# DCAN2 register map
Vendor: Texas Instruments
Peripheral module from a debugger description file (folder DM50x).
Registers are 32-bit, read-only, reset 0x0 unless marked. A register's access mark holds for its fields unless they carry their own. Offsets are as the file gives them; lines under a group give offsets from that group; [hi:lo] are bit positions; {n}, {i} and the like mark numbered series; 'fields as' and 'values as' point back to an identical list; <NAME> marks a mode.

## DCAN2 (part 1 of 2)
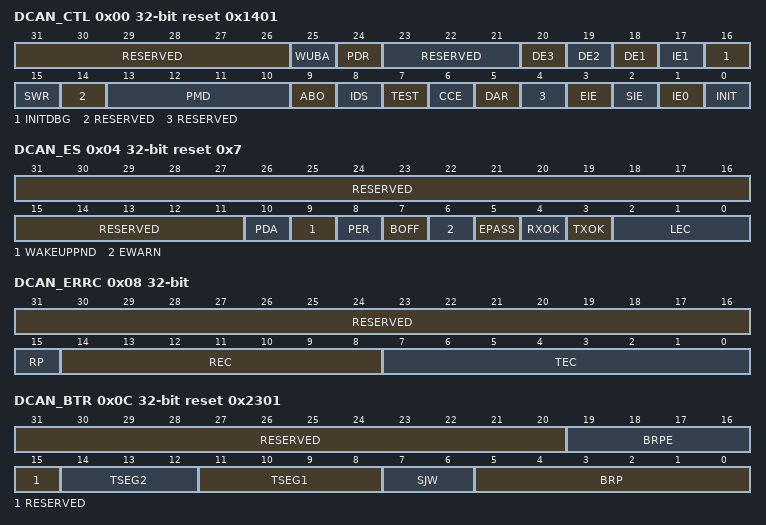
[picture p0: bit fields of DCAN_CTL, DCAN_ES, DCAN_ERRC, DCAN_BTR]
0x00 DCAN_CTL access per field reset 0x1401 — DCAN control register NOTE: The Bus-Off recovery sequence (refer to CAN specification) cannot be shortened by setting or resetting INIT bit. If the module goes Bus-Off, it will automatically set the INIT bit and stop all bus activities. When the INIT bit is cleared by the application again, the module will then wait for 129 occurrences of Bus Idle (129 × 11 consecutive recessive bits) before resuming normal operation. At the end of the bus-off recovery sequence, the error counters will be reset. After the INIT bit is reset, each time when a sequence of 11 recessive bits is monitored, a Bit0 error code is written to , enabling the software to check whether the CAN bus is stuck at dominant or continuously disturbed, and to monitor the proceeding of the bus-off recovery sequence.
  [31:26] RESERVED ro — These bits are always read as 0. Writes have no effect.
  [25] WUBA rw — Automatic wake up on bus activity when in local power-down mode. Note: The CAN message, which initiates the bus activity, cannot be received. This means that the first message received in power down and automatic wake-up mode, will be lost.
    0=CAN_0 (No detection of a dominant CAN bus level while in local power-down mode.); 1=CAN_CAN_1 (Detection of a dominant CAN bus level while in local power-down mode is enabled. On occurrence of a dominant CAN bus level, the wake up sequence is started (Additional information can be found inLocal Power-Down Mode).)
  [24] PDR rw — Request for local low power-down mode
    0=DCAN_INIT_0 (No application request for local low power-down mode. If the application has cleared this bit while DCAN in local power-down mode, also the INIT bit has to be cleared.); 1=DCAN_PDA_DCAN_1 (Local power-down mode has been requested by application. The DCAN will acknowledge the local power-down mode by setting bit PDA in the register. The local clocks will be turned off by DCAN internal logic (Additional information can be found in Local Power-Down Mode).)
  [23:21] RESERVED ro — These bits are always read as 0. Writes have no effect.
  [20] DE3 rw — Enable DMA request line for IF3. Note: A pending DMA request for IF3 remains active until first access to one of the IF3 registers.
    0=Disabled; 1=Enabled
  [19] DE2 rw — Enable DMA request line for IF2. Note: A pending DMA request for IF2 remains active until first access to one of the IF2 registers.
    0=Disabled; 1=Enabled
  [18] DE1 rw — Enable DMA request line for IF1. Note: A pending DMA request for IF1 remains active until first access to one of the IF1 registers.
    0=Disabled; 1=Enabled
  [17] IE1 rw — Interrupt line 1 enable
    0=INT1_0 (Disabled - Module interrupt INT1 is always low.); 1=INT1_1 (Enabled - interrupts will assert line INT1 to one; line remains active until pending interrupts are processed.)
  [16] INITDBG rw — Internal init state while debug access
    0=Not in debug mode, or debug mode requested but not entered; 1=DCAN_1 (Debug mode requested and internally entered; the DCAN is ready for debug accesses.)
  [15] SWR rw — Software reset enable. Note: To execute software reset, the following procedure is necessary:
    0=Normal_Operation; 1=OCP_1 (Module is forced to reset state. This bit will automatically get cleared after execution of software reset after one OCP clock cycle.)
  [14] RESERVED ro — This bit is always read as 0. Writes have no effect.
  [13:10] PMD rw — ECCon/offOthers: function enabled .
    5=function_disabled
  [9] ABO rw — Auto-Bus-On enable
    0=The_Auto-Bus-On_feature_is_disabled; 1=The_Auto-Bus-On_feature_is_enabled
  [8] IDS rw — Interruption debug support enable
    0=DCAN_0 (When Debug/Suspend mode is requested, DCAN will wait for a started transmission or reception to be completed before entering Debug/Suspend mode); 1=DCAN_1 (When Debug/Suspend mode is requested, DCAN will interrupt any transmission or reception, and enter Debug/Suspend mode immediately.)
  [7] TEST rw — Test mode enable
    0=Normal_Operation; 1=Test_Mode
  [6] CCE rw — Configuration change enable
    0=The software has no write access to the configuration registers; 1=INIT_1 (The software has write access to the configuration registers (when INIT bit is set).)
  [5] DAR rw — Disable automatic retransmission
    0=Automatic retransmission of not successful messages enabled; 1=Automatic_retransmission_disabled
  [4] RESERVED ro — This bit is always read as 0. Writes have no effect.
  [3] EIE rw — Error interrupt enable
    0=PER,_BOFF_EWARN_0 (Disabled - PER, BOFF and EWARN bits can not generate an interrupt.); 1=PER,_BOFF_EWARN_INT0_1 (Enabled - PER, BOFF and EWARN bits can generate an interrupt at INT0 line and affect the interrupt register.)
  [2] SIE rw — Status change interrupt enable
    0=WAKEUPPND,_RXOK,_TXOK_LEC_0 (Disabled - WAKEUPPND, RXOK, TXOK and LEC bits can not generate an interrupt.); 1=WAKEUPPND,_RXOK,_TXOK_LEC_INT0_1 (Enabled - WAKEUPPND, RXOK, TXOK and LEC can generate an interrupt at INT0 line and affect the interrupt register.)
  [1] IE0 rw — Interrupt line 0 enable
    0=INT0_0 (Disabled - Module interrupt INT0 is always low.); 1=INT0_1 (Enabled - interrupts will assert line INT0 to one; line remains active until pending interrupts are processed.)
  [0] INIT rw — Initialization
    0=Normal_operation; 1=Initialization_mode_is_entered
0x04 DCAN_ES access per field reset 0x7 — Error and Status Register Interrupts are generated by bits PER, BOFF and EWARN (if EIE bit in is 1) and by bits WAKEUPPND, RXOK, TXOK, and LEC (if SIE bit in is 1). A change of bit EPASS will not generate an interrupt. Reading the clears the WAKEUPPND, PER, RXOK and TXOK bits and set the LEC to value '7.' Additionally, the status interrupt value (0x8000) in the will be replaced by the next lower priority interrupt value. For debug support, the auto clear functionality of (clear of status flags by read) is disabled when in debug/suspend mode.
  [31:11] RESERVED ro — These bits are always read as 0. Writes have no effect.
  [10] PDA ro — Local power-down mode acknowledge
    0=DCAN_is_not_in_local_power-down_mode; 1=DCAN_DCAN_1 (Application request for setting DCAN to local power-down mode was successful. DCAN is in local power-down mode.)
  [9] WAKEUPPND ro — Wake up pending. This bit can be used by the software to identify the DCAN as the source to wake up the system. This bit will be reset ifDCAN_ES is read. .
    0=No_Wake_Up_is_requested_by_DCAN; 1=DCAN_CAN_1 (DCAN has initiated a wake up of the system due to dominant CAN bus while module power down.)
  [8] PER rw — Parity error detected. This bit will be reset ifDCAN_ES register is read.
    0=PER_0_r (No parity error has been detected since last read access.); 1=RAM._1 (The parity check mechanism has detected a parity error in the Message RAM.); 0=No_effect; 1=(EOI)_DCAN_PARITY_1 (End of interrupt (EOI) for parity error on DCAN_PARITY interrupt line)
  [7] BOFF ro — Bus-Off state
    0=The_CAN_module_is_not_bus-off_state; 1=The_CAN_module_is_in_bus-off_state
  [6] EWARN ro — Warning state
    0=Both error counters are below the error warning limit of 96; 1=At least one of the error counters has reached the error warning limit of 96
  [5] EPASS ro — Error passive state
    0=CAN_DCAN_0 (On CAN Bus error, the DCAN could send active error frames.); 1=CAN_CAN_1 (The CAN core is in the error passive state as defined in the CAN Specification.)
  [4] RXOK ro — Received a message successfully. This bit will be reset ifDCAN_ES register is read. .
    0=DCAN_0 (No message has been successfully received since the last time when this bit was read by the software. This bit is never reset by DCAN internal events.); 1=A_1 (A message has been successfully received since the last time when this bit was reset by a read access of the software (independent of the result of acceptance filtering).)
  [3] TXOK ro — Transmitted a message successfully. This bit will be reset ifDCAN_ES register is read. .
    0=DCAN_0 (No message has been successfully transmitted since the last time when this bit was read by the software. This bit is never reset by DCAN internal events.); 1=A_1 (A message has been successfully transmitted (error free and acknowledged by at least one other node) since the last time when this bit was reset by a read access of the software.)
  [2:0] LEC ro — Last error code. The LEC field indicates the type of the last error on the CAN bus. This field will be cleared to '0' when a message has been transferred (reception or transmission) without error.
    0=No_error; 1=Stuff error: More than five equal bits in a row have been detected in a part of a received message where this is not allowed; 2=A_2 (Form error: A fixed format part of a received frame has the wrong format.); 3=CAN_3 (Ack error: The message this CAN core transmitted was not acknowledged by another node.); 4=Bit1 error: During the transmission of a message (with the exception of the arbitration field), the device wanted to send a recessive level (bit of logical value '1'), but the monitored bus value was dominant; 5=Bit0 error: During the transmission of a message (or acknowledge bit, or active error flag, or overload flag), the device wanted to send a dominant level (logical value '0'), but the monitored bus level was recessive. During Bus-Off recovery, this status is set each time a sequence of 11 recessive bits has been monitored. This enables the software to monitor the proceeding of the Bus-Off recovery sequence (indicating the bus is not stuck at dominant or continuously disturbed).; 6=CRC_CRC_(CRC_CRC_6 (CRC error: In a received message, the CRC check sum was incorrect. (CRC received for an incoming message does not match the calculated CRC for the received data).); 7=CAN_LEC_7 (No CAN bus event was detected since the last time the software read. Any read access to re-initializes the LEC to value '7.')
0x08 DCAN_ERRC — Error Counter Register
  [31:16] RESERVED — These bits are always read as 0. Writes have no effect.
  [15] RP — Receive error passive
    0=The receive error counter is below the error passive level; 1=CAN_1 (The receive error counter has reached the error passive level as defined in the CAN specification.)
  [14:8] REC — Receive error counter. Actual state of the receive error counter
  [7:0] TEC — Transmit error counter. Actual state of the transmit error counter
0x0C DCAN_BTR access per field reset 0x2301 — Bit timing register This register is only writable if CCE and INIT bits in the are set. The CAN bit time may be programmed in the range of 8 to 25 time quanta The CAN time quantum may be programmed in the range of 1 to 1024 CAN_CLK periods.
  [31:20] RESERVED ro — These bits are always read as 0. Writes have no effect.
  [19:16] BRPE rw — Baud rate prescaler extension.Valid programmed values are 0 to 15. . By programming BRPE the baud rate prescaler can be extended to values up to 1024. .
  [15] RESERVED ro — These bits are always read as 0. Writes have no effect.
  [14:12] TSEG2 rw — Time segment after the sample pointValid programmed values are 0 to 7. . The actual TSeg2 value which is interpreted for the bit timing will be the programmed TSeg2 value + 1. .
  [11:8] TSEG1 rw — Time segment before the sample pointValid programmed values are 1 to15. . The actual TSeg1 value interpreted for the bit timing will be the programmed TSeg1 value + 1. .
  [7:6] SJW rw — Synchronization Jump WidthValid programmed values are 0 to 3. . The actual SJW value interpreted for the synchronization will be the programmed SJW value + 1. .
  [5:0] BRP rw — Baud rate prescalerValue by which the CAN_CLK frequency is divided for generating the bit time quanta. The bit time is built up from a multiple of this quanta. . Valid programmed values are 0 to 63. . The actual BRP value interpreted for the bit timing will be the programmed BRP value + 1. .
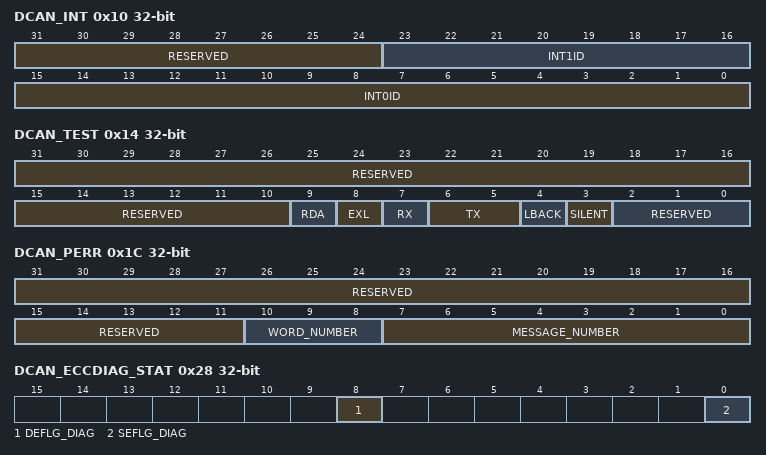
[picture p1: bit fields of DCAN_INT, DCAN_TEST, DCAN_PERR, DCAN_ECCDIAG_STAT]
0x10 DCAN_INT — Interrupt register
  [31:24] RESERVED — These bits are always read as 0. Writes have no effect.
  [23:16] INT1ID — Interrupt 1 Identifier (indicates the message object with the highest pending interrupt)0x01-0x80: Number of message object which caused the interrupt. . 0x81-0xFF: Unused . If several interrupts are pending, will point to the pending interrupt with the highest priority. The INT1 interrupt line remains active until INT1ID reaches value 0 (the cause of the interrupt is reset) or until IE1 is cleared. . A message interrupt is cleared by clearing the message object's IntPnd bit. . Among the message interrupts, the message object's interrupt priority decreases with increasing message number. .
    0=No_interrupt_is_pending
  [15:0] INT0ID — Interrupt Identifier (the number here indicates the source of the interrupt)0x0001-0x0080: Number of message object which caused the interrupt. . 0x0081-0x7FFF: Unused . 0x8001-0xFFFF: Unused . If several interrupts are pending,DCAN_INTwill point to the pending interrupt with the highest priority. The INT0 interrupt line remains active until INT0ID reaches value 0 (the cause of the interrupt is reset) or until IE0 is cleared. . The Status interrupt has the highest priority. Among the message interrupts, the message object's interrupt priority decreases with increasing message number. .
    0=No_interrupt_is_pending; 0x8000=value_is_not_0x07
0x14 DCAN_TEST access per field (reset mask 0xFFFFFF7F) — Test Register For all test modes, the TEST bit in control register needs to be set to 1. If TEST bit is set, the RDA, EXL, TX1, TX0, LBACK and SILENT bits are writable. Bit RX monitors the state of pin CAN_RX and therefore is only readable. All test register functions are disabled when TEST bit is cleared.
  [31:10] RESERVED ro — These bits are always read as 0. Writes have no effect.
  [9] RDA rw — RAM direct access enable
    0=Normal_operation; 1=RAM_1 (Direct access to the RAM is enabled while in test mode)
  [8] EXL rw — External loopback mode. When the internal loop-back mode is active (bit LBACK is set), bit EXL will be ignored.
    0=Disabled; 1=Enabled
  [7] RX ro — Receive pin. Monitors the actual value of the CAN_RX pin
    0=The_CAN_bus_is_dominant; 1=The_CAN_bus_is_recessive
  [6:5] TX rw — Control of CAN_TX pin. Setting Tx[1:0] other than '00' will disturb message transfer.
    0=CAN_TX_CAN_0 (Normal operation, CAN_TX is controlled by the CAN core.); 1=CAN_TX_1 (Sample point can be monitored at CAN_TX pin.); 2=CAN_TX_pin_drives_a_dominant_value; 3=CAN_TX_pin_drives_a_recessive_value
  [4] LBACK rw — Loopback mode. When the internal loop-back mode is active (bit LBACK is set), bit EXL will be ignored.
    0=Disabled; 1=Enabled
  [3] SILENT rw — Silent mode
    0=Disabled; 1=Enabled
  [2:0] RESERVED ro — These bits are always read as 0. Writes have no effect.
0x1C DCAN_PERR (reset mask 0xFFFFF800) — Parity Error Code Register If a parity error is detected, the PER flag will be set in the . This bit is not reset by the parity check mechanism; it must be reset by reading . In addition to the PER flag, the parity error code register will indicate the memory area where the parity error has been detected (message number and word number). If more than one word with a parity error was detected, the highest word number with a parity error will be displayed. After a parity error has been detected, the register will hold the last error code until power is removed.
  [31:11] RESERVED — These bits are always read as 0. Writes have no effect.
  [10:8] WORD_NUMBER — Word number where parity error has been detectedRDA word number (1 to 5) of the message object (according to the message RAM representation in RDA mode). .
  [7:0] MESSAGE_NUMBER — Message object number where parity error has been detected (0x01-0x80)
0x20 DCAN_REL reset not defined — Core revision register
  [31:0] REVISION — DCAN core revision number
0x24 DCAN_ECCDIAG access per field reset 0xA — ECC Diagnostic Register. This register is writable only in privileged mode.
  [3:0] ECCDIAG rw — SECDED diagnostic mode enable/disable 0x5: Diagnostic mode is enabled. Single and double bit errors are shown in the DCAN_ECCDIAG_STAT and the DCAN_ECC_CS. A double bit error (or single bit error with single bit error correction disabled) also triggers the parity interrupt flag (PER). Memory mapping of ECC RAM is enabled 0xA: Diagnostic mode is disabled, single and double bit errors are shown only in the DCAN_ECC_CS.
0x28 DCAN_ECCDIAG_STAT access per field — ECC Diagnostic Status Register
  [8] DEFLG_DIAG rw — Double bit error flag diagnostic Read 0: No double bit error detected. Write 0: The bit is unchanged. Read 1: Double bit error detected in diagnostic mode. Write 1: The bit is cleared to 0.
  [0] SEFLG_DIAG rw — Single bit error flag diagnostic Read 0: No single bit error detected. Write 0: The bit is unchanged. Read 1: Single bit error detected in diagnostic mode. Write 1: The bit is cleared to 0.
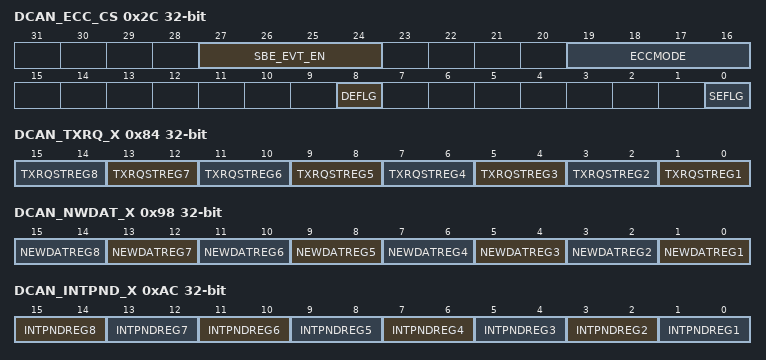
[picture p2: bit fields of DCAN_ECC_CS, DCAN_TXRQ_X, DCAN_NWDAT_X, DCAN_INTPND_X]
0x2C DCAN_ECC_CS access per field (reset mask 0xF0F0FFFF) — ECC Control and Status Register
  [27:24] SBE_EVT_EN rw — Enable/disable SECDED single bit error event (CAN_SERR signal). Write in privileged mode only. 0x5: SECDED single bit error event is disabled, single bit errors are not signaled with a high pulse on CAN_SERR signal. Others: SECDED single bit error event is enabled, single bit errors are signaled with a high pulse on CAN_SERR signal.
  [19:16] ECCMODE rw — Enable/disable SECDED single bit error correction. Write in privileged mode only. 0x5: SECDED single bit error correction disabled Others: SECDED single bit error correction enabled
  [8] DEFLG rw — Double bit error flag Read 0: No double bit error detected. Write 0: The bit is unchanged. Read 1: Double bit error detected. Write 1: The bit is cleared to 0.
  [0] SEFLG rw — Single bit error flag Read 0: No single bit error detected. Write 0: The bit is unchanged. Read 1: Single bit error detected. Write 1: The bit is cleared to 0.
0x30 DCAN_ECC_SERR access per field (reset mask 0xFFFFFF00) — ECC Single Bit Error Code Register. If an ECC single bit error is detected, the SEFLG flag will be set in the . In addition, MESSAGE_NUMBER will indicate the memory area where the single bit error has been detected (message object number only). If more than one word with an ECC single bit error was detected, the highest word number with an ECC single bit error error will be displayed. After an ECC single bit error has been detected, the register will hold the last error code until power is removed.
  [7:0] MESSAGE_NUMBER rw — Message object number where ECC single bit error has been detected. 0x0: Reserved
0x80 DCAN_ABOTR rw — Auto-Bus-On Time Register On write access to the while Auto-Bus-On timer is running, the Auto-Bus-On procedure will be aborted. During Debug/Suspend mode, running Auto-Bus-On timer will be paused.
  [31:0] ABO_TIME — Number of OCP clock cycles before a Bus-Off recovery sequence is started by clearing the INIT bit. This function has to be enabled by setting bit ABO inDCAN_CTL. The Auto-Bus-On timer is realized by a 32-bit counter which starts to count down to zero when the module goes Bus-Off. The counter will be reloaded with the preload value of the DCAN_ABOTR after this phase.
0x84 DCAN_TXRQ_X — Transmission Request X Register The software can detect if one or more bits in the different transmission request registers are set. Each register bit represents a group of eight message objects. If at least one of the TxRqst bits of these message objects are set, the corresponding bit in the transmission request X register will be set.
  [2n-1:2n-2] TXRQSTREG{n} (n=1..8) — Transmission request bits (aggregate for {16n-15}-{16n} message objects). Lower bit represents first 8 message objects. Higher bit represents second 8 message objects.
0x88 DCAN_TXRQ12 — Transmission Request Register This register holds the TxRqst bits of the implemented message objects. By reading out these bits, the software can check for pending transmission requests. The TxRqst bit in a specific message object can be set/reset by the software via the IF1/IF2 message interface registers, or by the message handler after reception of a remote frame or after a successful transmission.
  [31:0] TXRQS — Transmission request bits (for 1-32 message objects) 0: No transmission has been requested for this message object. 1: The transmission of this message object is requested and is not yet done.
0x8C DCAN_TXRQ34 — Transmission Request Register This register holds the TxRqst bits of the implemented message objects. By reading out these bits, the software can check for pending transmission requests. The TxRqst bit in a specific message object can be set/reset by the software via the IF1/IF2 message interface registers, or by the message handler after reception of a remote frame or after a successful transmission.
  [31:0] TXRQS — Transmission request bits (for 33-64 message objects) 0: No transmission has been requested for this message object. 1: The transmission of this message object is requested and is not yet done.
0x90 DCAN_TXRQ56 — Transmission Request Register This register holds the TxRqst bits of the implemented message objects. By reading out these bits, the software can check for pending transmission requests. The TxRqst bit in a specific message object can be set/reset by the software via the IF1/IF2 message interface registers, or by the message handler after reception of a remote frame or after a successful transmission.
  [31:0] TXRQS — Transmission request bits (for 65-96 message objects) 0: No transmission has been requested for this message object. 1: The transmission of this message object is requested and is not yet done.
0x94 DCAN_TXRQ78 — Transmission Request Register This register holds the TxRqst bits of the implemented message objects. By reading out these bits, the software can check for pending transmission requests. The TxRqst bit in a specific message object can be set/reset by the software via the IF1/IF2 message interface registers, or by the message handler after reception of a remote frame or after a successful transmission.
  [31:0] TXRQS — Transmission request bits (for 97-128 message objects) 0: No transmission has been requested for this message object. 1: The transmission of this message object is requested and is not yet done.
0x98 DCAN_NWDAT_X — New Data X Register With the new data X register, the software can detect if one or more bits in the different new data registers are set. Each register bit represents a group of eight message objects. If at least on of the NewDat bits of these message objects are set, the corresponding bit in the new data X register will be set
  [2n-1:2n-2] NEWDATREG{n} (n=1..8) — New data bits (aggregate for {16n-15}-{16n} message objects). Lower bit represents first 8 message objects. Higher bit represents second 8 message objects.
0x9C DCAN_NWDAT12 — New Data Register This register hold the NewDat bits of the implemented message objects. By reading out these bits, the software can check for new data in the message objects. The NewDat bit of a specific message object can be set/reset by the software via the IF1/IF2 interface register sets, or by the message handler after reception of a data frame or after a successful transmission.
  [31:0] NEWDAT — New Data Bits (for 1-32 message objects) 0: No new data has been written into the data portion of this message object by the Message Handler since the last time when this flag was cleared by the software. 1: The Message Handler or the software has written new data into the data portion of this message object.
0xA0 DCAN_NWDAT34 — New Data Register This register hold the NewDat bits of the implemented message objects. By reading out these bits, the software can check for new data in the message objects. The NewDat bit of a specific message object can be set/reset by the software via the IF1/IF2 interface register sets, or by the message handler after reception of a data frame or after a successful transmission.
  [31:0] NEWDAT — New Data Bits (for 33-64 message objects) 0: No new data has been written into the data portion of this message object by the Message Handler since the last time when this flag was cleared by the software. 1: The Message Handler or the software has written new data into the data portion of this message object.
0xA4 DCAN_NWDAT56 — New Data Register This register hold the NewDat bits of the implemented message objects. By reading out these bits, the software can check for new data in the message objects. The NewDat bit of a specific message object can be set/reset by the software via the IF1/IF2 interface register sets, or by the message handler after reception of a data frame or after a successful transmission.
  [31:0] NEWDAT — New Data Bits (for 65-96 message objects) 0: No new data has been written into the data portion of this message object by the Message Handler since the last time when this flag was cleared by the software. 1: The Message Handler or the software has written new data into the data portion of this message object.
0xA8 DCAN_NWDAT78 — New Data Register This register hold the NewDat bits of the implemented message objects. By reading out these bits, the software can check for new data in the message objects. The NewDat bit of a specific message object can be set/reset by the software via the IF1/IF2 interface register sets, or by the message handler after reception of a data frame or after a successful transmission.
  [31:0] NEWDAT — New Data Bits (for 97-128 message objects) 0: No new data has been written into the data portion of this message object by the Message Handler since the last time when this flag was cleared by the software. 1: The Message Handler or the software has written new data into the data portion of this message object.
0xAC DCAN_INTPND_X — Interrupt Pending X Register With the interrupt pending X register, the software can detect if one or more bits in the different interrupt pending registers are set. Each bit of this register represents a group of eight message objects. If at least one of the IntPnd bits of these message objects are set, the corresponding bit in the interrupt pending X register will be set.
  [15:14] INTPNDREG8 — Interrupt Pending bits (aggregate for 113-128 message objects). Lower bit represents first 8 message objects. Higher bit represents second 8 message objects.
  [13:12] INTPNDREG7 — Interrupt Pending bits (aggregate for 97-112 message objects). Lower bit represents first 8 message objects. Higher bit represents second 8 message objects.
  [11:10] INTPNDREG6 — Interrupt Pendingbits (aggregate for 81-96 message objects). Lower bit represents first 8 message objects. Higher bit represents second 8 message objects.
  [2n-1:2n-2] INTPNDREG{n} (n=1..5) — Interrupt Pending bits (aggregate for {16n-15}-{16n} message objects). Lower bit represents first 8 message objects. Higher bit represents second 8 message objects.
0xB0 DCAN_INTPND12 — Interrupt Pending Register This register holds the IntPnd bits of the implemented message objects. By reading out these bits, the software can check for pending interrupts in the message objects. The IntPnd bit of a specific message object can be set/reset by the software via the IF1/IF2 interface register sets, or by the message handler after a reception or a successful transmission.
  [31:0] INTPND — Interrupt Pending Bits (for 1-32 message objects)
    0=This message object is not the source of an interrupt; 1=This message object is the source of an interrupt
0xB4 DCAN_INTPND34 — Interrupt Pending Register This register holds the IntPnd bits of the implemented message objects. By reading out these bits, the software can check for pending interrupts in the message objects. The IntPnd bit of a specific message object can be set/reset by the software via the IF1/IF2 interface register sets, or by the message handler after a reception or a successful transmission.
  [31:0] INTPND — Interrupt Pending Bits (for 33-64 message objects)
    values as DCAN_INTPND12.INTPND
0xB8 DCAN_INTPND56 — Interrupt Pending Register This register holds the IntPnd bits of the implemented message objects. By reading out these bits, the software can check for pending interrupts in the message objects. The IntPnd bit of a specific message object can be set/reset by the software via the IF1/IF2 interface register sets, or by the message handler after a reception or a successful transmission.
  [31:0] INTPND — Interrupt Pending Bits (for 65-96 message objects)
    values as DCAN_INTPND12.INTPND
0xBC DCAN_INTPND78 — Interrupt Pending Register This register holds the IntPnd bits of the implemented message objects. By reading out these bits, the software can check for pending interrupts in the message objects. The IntPnd bit of a specific message object can be set/reset by the software via the IF1/IF2 interface register sets, or by the message handler after a reception or a successful transmission.
  [31:0] INTPND — Interrupt Pending Bits (for 97-128 message objects)
    values as DCAN_INTPND12.INTPND
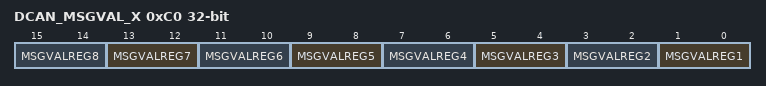
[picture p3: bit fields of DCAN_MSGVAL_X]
0xC0 DCAN_MSGVAL_X — Message Valid X Register With the message valid X register, the software can detect if one or more bits in the different message valid registers are set. Each bit of this register represents a group of eight message objects. If at least one of the MsgVal bits of these message objects are set, the corresponding bit in the message valid X register will be set.
  [2n-1:2n-2] MSGVALREG{n} (n=1..8) — Message valid bits (aggregate for {16n-15}-{16n} message objects). Lower bit represents first 8 message objects. Higher bit represents second 8 message objects.
0xC4 DCAN_MSGVAL12 — Message Valid Register These registers hold the MsgVal bits of the implemented message objects. By reading out these bits, the software can check which message objects are valid. The MsgVal bit of a specific message object can be set/reset by the software via the IF1/IF2 interface register sets, or by the message handler after a reception or a successful transmission
  [31:0] MSGVAL — Message valid Bits (for 1-32 message objects)
    0=This message object is ignored by the message handler; 1=This message object is configured and will be considered by the message handler
0xC8 DCAN_MSGVAL34 — Message Valid Register These registers hold the MsgVal bits of the implemented message objects. By reading out these bits, the software can check which message objects are valid. The MsgVal bit of a specific message object can be set/reset by the software via the IF1/IF2 interface register sets, or by the message handler after a reception or a successful transmission
  [31:0] MSGVAL — Message valid Bits (for 33-64 message objects)
    values as DCAN_MSGVAL12.MSGVAL
0xCC DCAN_MSGVAL56 — Message Valid Register These registers hold the MsgVal bits of the implemented message objects. By reading out these bits, the software can check which message objects are valid. The MsgVal bit of a specific message object can be set/reset by the software via the IF1/IF2 interface register sets, or by the message handler after a reception or a successful transmission
  [31:0] MSGVAL — Message valid Bits (for 65-96 message objects)
    values as DCAN_MSGVAL12.MSGVAL
0xD0 DCAN_MSGVAL78 — Message Valid Register These registers hold the MsgVal bits of the implemented message objects. By reading out these bits, the software can check which message objects are valid. The MsgVal bit of a specific message object can be set/reset by the software via the IF1/IF2 interface register sets, or by the message handler after a reception or a successful transmission
  [31:0] MSGVAL — Message valid Bits (for 97-128 message objects)
    values as DCAN_MSGVAL12.MSGVAL
0xD8 DCAN_INTMUX12 rw — Interrupt Multiplexer Register The IntMux flag determine for each message object, which of the two interrupt lines (INT0 or INT1) will be asserted when the IntPnd of this message object is set. Both interrupt lines can be globally enabled or disabled by setting or clearing IE0 and IE1 bits in . The IntPnd bit of a specific message object can be set or reset by the software via the IF1/IF2 interface register sets, or by message handler after reception or successful transmission of a frame. This will also affect the INT0ID resp. INT1ID flags in the register.
  [31:0] INTMUX — Multiplexes IntPnd value to either INT0 or INT1 interrupt lines (bit 0 -&gt; last implemented message object) ( bits 1:31 -&gt; 1-31 message objects)
    0=INT0_0 (INT0 line is active if corresponding IntPnd flag is one.); 1=INT1_1 (INT1 line is active if corresponding IntPnd flag is one.)
0xDC DCAN_INTMUX34 rw — Interrupt Multiplexer Register The IntMux flag determine for each message object, which of the two interrupt lines (INT0 or INT1) will be asserted when the IntPnd of this message object is set. Both interrupt lines can be globally enabled or disabled by setting or clearing IE0 and IE1 bits in CAN control register. The IntPnd bit of a specific message object can be set or reset by the software via the IF1/IF2 interface register sets, or by message handler after reception or successful transmission of a frame. This will also affect the INT0ID resp INT1ID flags in the register.
  [31:0] INTMUX — Multiplexes IntPnd value to either INT0 or INT1 interrupt lines ( bits 0:31 -&gt; 32-63 message objects)
    values as DCAN_INTMUX12.INTMUX
0xE0 DCAN_INTMUX56 rw — Interrupt Multiplexer Register The IntMux flag determine for each message object, which of the two interrupt lines (INT0 or INT1) will be asserted when the IntPnd of this message object is set. Both interrupt lines can be globally enabled or disabled by setting or clearing IE0 and IE1 bits in CAN control register. The IntPnd bit of a specific message object can be set or reset by the software via the IF1/IF2 interface register sets, or by message handler after reception or successful transmission of a frame. This will also affect the INT0ID resp INT1ID flags in the register.
  [31:0] INTMUX — Multiplexes IntPnd value to either INT0 or INT1 interrupt lines ( bits 0:31 -&gt; 64-95 message objects)
    values as DCAN_INTMUX12.INTMUX
0xE4 DCAN_INTMUX78 rw — Interrupt Multiplexer Register The IntMux flag determine for each message object, which of the two interrupt lines (INT0 or INT1) will be asserted when the IntPnd of this message object is set. Both interrupt lines can be globally enabled or disabled by setting or clearing IE0 and IE1 bits in CAN control register. The IntPnd bit of a specific message object can be set or reset by the software via the IF1/IF2 interface register sets, or by message handler after reception or successful transmission of a frame. This will also affect the INT0ID resp INT1ID flags in the register.
  [31:0] INTMUX — Multiplexes IntPnd value to either INT0 or INT1 interrupt lines ( bits 0:31 -&gt; 96-127 message objects)
    values as DCAN_INTMUX12.INTMUX
